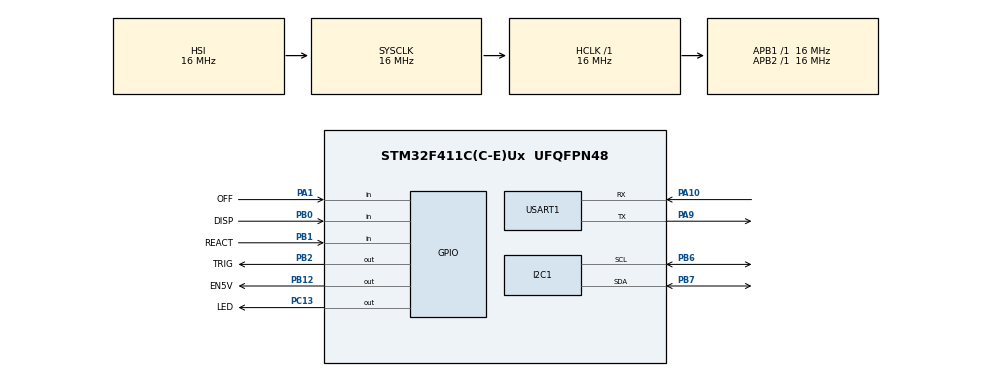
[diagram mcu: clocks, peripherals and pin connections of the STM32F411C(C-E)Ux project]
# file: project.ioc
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Mcu.Family=STM32F4
Mcu.Name=STM32F411C(C-E)Ux
Mcu.Package=UFQFPN48
NVIC.I2C1_EV_IRQn=true\:0\:0\:false\:false\:true\:true\:true\:true
NVIC.PriorityGroup=NVIC_PRIORITYGROUP_4
NVIC.USART1_IRQn=true\:0\:0\:false\:false\:true\:true\:true\:true
PA0-WKUP.GPIO_Label=ON
PA0-WKUP.Mode=SYS_WakeUp0
PA0-WKUP.Signal=SYS_WKUP
PA1.GPIO_Label=OFF
PA1.Signal=GPIO_Input
PA10.Mode=Asynchronous
PA10.Signal=USART1_RX
PA13.Mode=Trace_Asynchronous_SW
PA13.Signal=SYS_JTMS-SWDIO
PA14.Mode=Trace_Asynchronous_SW
PA14.Signal=SYS_JTCK-SWCLK
PA9.Mode=Asynchronous
PA9.Signal=USART1_TX
PB0.GPIO_Label=DISP
PB0.Signal=GPIO_Input
PB1.GPIO_Label=REACT
PB1.Signal=GPIO_Input
PB12.GPIO_Label=EN5V
PB12.Signal=GPIO_Output
PB2.GPIO_Label=TRIG
PB2.Signal=GPIO_Output
PB3.Mode=Trace_Asynchronous_SW
PB3.Signal=SYS_JTDO-SWO
PB6.Mode=I2C
PB6.Signal=I2C1_SCL
PB7.Mode=I2C
PB7.Signal=I2C1_SDA
PC13-ANTI_TAMP.GPIO_Label=LED
PC13-ANTI_TAMP.Signal=GPIO_Output
ProjectManager.HeapSize=0x200
ProjectManager.StackSize=0x400
ProjectManager.TargetToolchain=STM32CubeIDE
RCC.AHBFreq_Value=16000000
RCC.APB1Freq_Value=16000000
RCC.APB1TimFreq_Value=16000000
RCC.APB2Freq_Value=16000000
RCC.APB2TimFreq_Value=16000000
RCC.CortexFreq_Value=16000000
RCC.HCLKFreq_Value=16000000
RCC.HSE_VALUE=25000000
RCC.HSI_VALUE=16000000
RCC.LSE_VALUE=32768
RCC.SYSCLKFreq_VALUE=16000000
RCC.VCOOutputFreq_Value=192000000
USART1.VirtualMode=VM_ASYNC
board=custom

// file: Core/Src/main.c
/* USER CODE BEGIN Header */
/**
  ******************************************************************************
  * @file           : main.c
  * @brief          : Main program body
  ******************************************************************************
  * @attention
  *
  * Copyright (c) 2025 STMicroelectronics.
  * All rights reserved.
  *
  * This software is licensed under terms that can be found in the LICENSE file
  * in the root directory of this software component.
  * If no LICENSE file comes with this software, it is provided AS-IS.
  *
  ******************************************************************************
  */
/* USER CODE END Header */
#include "main.h"

/* USER CODE BEGIN Includes */
#include <stdbool.h>
#include <stdio.h>
#include "func.h"
/* USER CODE END Includes */

I2C_HandleTypeDef hi2c1;

UART_HandleTypeDef huart1;

void SystemClock_Config(void);
static void MX_GPIO_Init(void);
static void MX_I2C1_Init(void);
static void MX_USART1_UART_Init(void);

int main(void)
{

  /* MCU Configuration--------------------------------------------------------*/

  /* Reset of all peripherals, Initializes the Flash interface and the Systick. */
  HAL_Init();

  /* Configure the system clock */
  SystemClock_Config();

  /* Initialize all configured peripherals */
  MX_GPIO_Init();
  MX_I2C1_Init();
  MX_USART1_UART_Init();
  /* USER CODE BEGIN 2 */
  user_code_2();
  /* USER CODE END 2 */

  /* Infinite loop */
  while (1)
  {

    /* USER CODE BEGIN 3 */
    user_code_3();
  /* USER CODE END 3 */
  }
}
void SystemClock_Config(void)
{
  RCC_OscInitTypeDef RCC_OscInitStruct = {0};
  RCC_ClkInitTypeDef RCC_ClkInitStruct = {0};

  /** Configure the main internal regulator output voltage
  */
  __HAL_RCC_PWR_CLK_ENABLE();
  __HAL_PWR_VOLTAGESCALING_CONFIG(PWR_REGULATOR_VOLTAGE_SCALE1);

  /** Initializes the RCC Oscillators according to the specified parameters
  * in the RCC_OscInitTypeDef structure.
  */
  RCC_OscInitStruct.OscillatorType = RCC_OSCILLATORTYPE_HSI;
  RCC_OscInitStruct.HSIState = RCC_HSI_ON;
  RCC_OscInitStruct.HSICalibrationValue = RCC_HSICALIBRATION_DEFAULT;
  RCC_OscInitStruct.PLL.PLLState = RCC_PLL_NONE;
  if (HAL_RCC_OscConfig(&RCC_OscInitStruct) != HAL_OK)
  {
    Error_Handler();
  }

  /** Initializes the CPU, AHB and APB buses clocks
  */
  RCC_ClkInitStruct.ClockType = RCC_CLOCKTYPE_HCLK|RCC_CLOCKTYPE_SYSCLK
                              |RCC_CLOCKTYPE_PCLK1|RCC_CLOCKTYPE_PCLK2;
  RCC_ClkInitStruct.SYSCLKSource = RCC_SYSCLKSOURCE_HSI;
  RCC_ClkInitStruct.AHBCLKDivider = RCC_SYSCLK_DIV1;
  RCC_ClkInitStruct.APB1CLKDivider = RCC_HCLK_DIV1;
  RCC_ClkInitStruct.APB2CLKDivider = RCC_HCLK_DIV1;

  if (HAL_RCC_ClockConfig(&RCC_ClkInitStruct, FLASH_LATENCY_0) != HAL_OK)
  {
    Error_Handler();
  }
}

static void MX_I2C1_Init(void)
{

  hi2c1.Instance = I2C1;
  hi2c1.Init.ClockSpeed = 100000;
  hi2c1.Init.DutyCycle = I2C_DUTYCYCLE_2;
  hi2c1.Init.OwnAddress1 = 0;
  hi2c1.Init.AddressingMode = I2C_ADDRESSINGMODE_7BIT;
  hi2c1.Init.DualAddressMode = I2C_DUALADDRESS_DISABLE;
  hi2c1.Init.OwnAddress2 = 0;
  hi2c1.Init.GeneralCallMode = I2C_GENERALCALL_DISABLE;
  hi2c1.Init.NoStretchMode = I2C_NOSTRETCH_DISABLE;
  if (HAL_I2C_Init(&hi2c1) != HAL_OK)
  {
    Error_Handler();
  }

}

static void MX_USART1_UART_Init(void)
{

  huart1.Instance = USART1;
  huart1.Init.BaudRate = 115200;
  huart1.Init.WordLength = UART_WORDLENGTH_8B;
  huart1.Init.StopBits = UART_STOPBITS_1;
  huart1.Init.Parity = UART_PARITY_NONE;
  huart1.Init.Mode = UART_MODE_TX_RX;
  huart1.Init.HwFlowCtl = UART_HWCONTROL_NONE;
  huart1.Init.OverSampling = UART_OVERSAMPLING_16;
  if (HAL_UART_Init(&huart1) != HAL_OK)
  {
    Error_Handler();
  }

}

static void MX_GPIO_Init(void)
{
  GPIO_InitTypeDef GPIO_InitStruct = {0};

  /* GPIO Ports Clock Enable */
  __HAL_RCC_GPIOC_CLK_ENABLE();
  __HAL_RCC_GPIOA_CLK_ENABLE();
  __HAL_RCC_GPIOB_CLK_ENABLE();

  /*Configure GPIO pin Output Level */
  HAL_GPIO_WritePin(LED_GPIO_Port, LED_Pin, GPIO_PIN_RESET);

  /*Configure GPIO pin Output Level */
  HAL_GPIO_WritePin(GPIOB, TRIG_Pin|EN5V_Pin, GPIO_PIN_RESET);

  /*Configure GPIO pin : LED_Pin */
  GPIO_InitStruct.Pin = LED_Pin;
  GPIO_InitStruct.Mode = GPIO_MODE_OUTPUT_PP;
  GPIO_InitStruct.Pull = GPIO_NOPULL;
  GPIO_InitStruct.Speed = GPIO_SPEED_FREQ_LOW;
  HAL_GPIO_Init(LED_GPIO_Port, &GPIO_InitStruct);

  /*Configure GPIO pin : OFF_Pin */
  GPIO_InitStruct.Pin = OFF_Pin;
  GPIO_InitStruct.Mode = GPIO_MODE_INPUT;
  GPIO_InitStruct.Pull = GPIO_NOPULL;
  HAL_GPIO_Init(OFF_GPIO_Port, &GPIO_InitStruct);

  /*Configure GPIO pins : DISP_Pin REACT_Pin */
  GPIO_InitStruct.Pin = DISP_Pin|REACT_Pin;
  GPIO_InitStruct.Mode = GPIO_MODE_INPUT;
  GPIO_InitStruct.Pull = GPIO_NOPULL;
  HAL_GPIO_Init(GPIOB, &GPIO_InitStruct);

  /*Configure GPIO pins : TRIG_Pin EN5V_Pin */
  GPIO_InitStruct.Pin = TRIG_Pin|EN5V_Pin;
  GPIO_InitStruct.Mode = GPIO_MODE_OUTPUT_PP;
  GPIO_InitStruct.Pull = GPIO_NOPULL;
  GPIO_InitStruct.Speed = GPIO_SPEED_FREQ_LOW;
  HAL_GPIO_Init(GPIOB, &GPIO_InitStruct);

}

void Error_Handler(void)
{
  __disable_irq();
  while (1)
  {
  }
}
